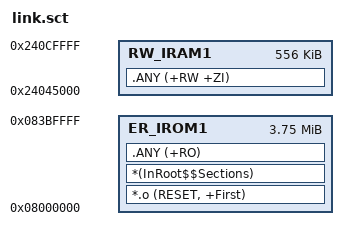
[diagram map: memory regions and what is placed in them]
; *************************************************************
; *** Scatter-Loading Description File generated by uVision ***
; *************************************************************

LR_IROM1 0x08000000 0x003C0000  {    ; GD32H759I 3840KB flash
  ER_IROM1 0x08000000 0x003C0000  {  ; load address = execution address
   *.o (RESET, +First)
   *(InRoot$$Sections)
   .ANY (+RO)
  }
  ; Keep the vendor framebuffer at 0x24005000..0x24044bff.  RW/ZI starts
  ; after that reserved region so startup data cannot overwrite the scanout.
  RW_IRAM1 0x24045000 0x0008B000  {  ; AXI SRAM ends at 0x240D0000 (556 KiB remain)
   .ANY (+RW +ZI)
  }
}

